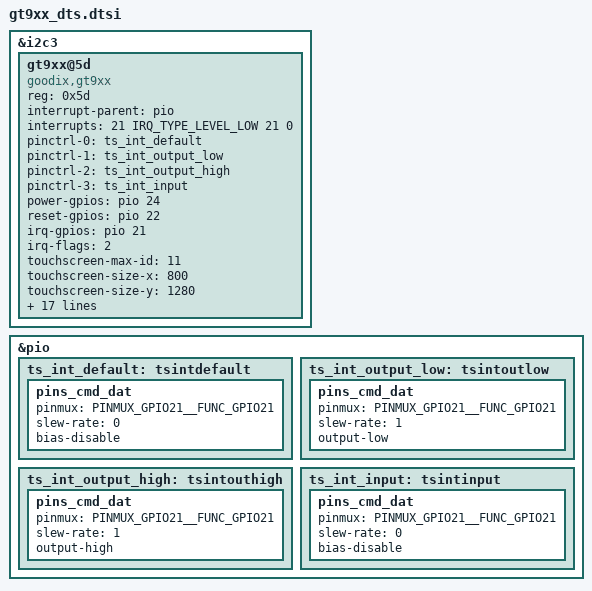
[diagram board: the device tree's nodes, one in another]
// SPDX-License-Identifier: GPL-2.0+
/*
 * Copyright (c) 2019 MediaTek Inc.
 */
&i2c3 {
	gt9xx@5d {
		compatible = "goodix,gt9xx";
		reg = <0x5d>; 
		status = "okay";
		interrupt-parent = <&pio>;
		interrupts = <21 IRQ_TYPE_LEVEL_LOW 21 0>;
		pinctrl-names = "default", "int-output-low","int-output-high", "int-input";
		pinctrl-0 = <&ts_int_default>;
		pinctrl-1 = <&ts_int_output_low>;
		pinctrl-2 = <&ts_int_output_high>;
		pinctrl-3 = <&ts_int_input>;
	
		power-gpios = <&pio 24 0>;
		reset-gpios = <&pio 22 0>;
		irq-gpios = <&pio 21 0>;
		irq-flags = <2>;
	
		touchscreen-max-id = <11>;
		touchscreen-size-x = <800>;
		touchscreen-size-y = <1280>;
		touchscreen-max-w = <512>;
		touchscreen-max-p = <512>;
		touchscreen-key-map = <172>, <158>; /*KEY_HOMEPAGE=172, KEY_BACK=158，KEY_MENU=139*/
		
		goodix,slide-wakeup = <0>;
		goodix,type-a-report = <0>;
		goodix,driver-send-cfg = <0>;
		goodix,resume-in-workqueue = <0>;
		goodix,int-sync = <0>;
		goodix,swap-x2y = <0>;
		goodix,reverse-x = <0>;
		goodix,reverse-y = <0>;
		goodix,esd-protect = <1>;
		goodix,auto-update-cfg = <0>;
		goodix,power-off-sleep = <0>;
		goodix,pen-suppress-finger = <0>;
		goodix,cfg-group0 = [
			63 20 03 00 05 0A 3D 00 01 08 1E 08 5A 3C 03 05 00 00 00 00 00 00 04 18 1A 1E 14 90 30 AA 2E 30 12 0C 00 00 00 DA 03 11 00 00 00 00 00 00 00 00 00 00 00 1E 46 94 D5 13 0C 87 00 04 A5 20 00 91 26 00 81 2D 00 73 36 00 69 40 00 69 00 00 00 00 00 00 00 00 00 00 00 00 00 00 00 00 00 00 00 00 00 00 00 00 00 00 00 00 10 00 00 00 00 00 00 00 00 01 04 05 06 07 08 09 0C 0D 0E 0F 10 11 14 15 16 17 18 19 00 00 00 00 00 00 00 00 00 00 00 02 04 06 07 08 0A 0C 0D 0E 0F 10 11 12 13 14 19 1B 1C 1E 1F 20 21 22 23 24 25 26 27 28 29 2A 00 00 00 00 00 00 00 00 00 00 DA 01
		];
	};
};

&pio {
	ts_int_default: tsintdefault {
		pins_cmd_dat {
			pinmux = <PINMUX_GPIO21__FUNC_GPIO21>;
			slew-rate = <0>;
			bias-disable;
		};
	};
	ts_int_output_low: tsintoutlow {
		pins_cmd_dat {
			pinmux = <PINMUX_GPIO21__FUNC_GPIO21>;
			slew-rate = <1>;
			output-low;
		};
	};
	ts_int_output_high: tsintouthigh {
		pins_cmd_dat {
			pinmux = <PINMUX_GPIO21__FUNC_GPIO21>;
			slew-rate = <1>;
			output-high;
		};
	};
	ts_int_input: tsintinput {
		pins_cmd_dat {
			pinmux = <PINMUX_GPIO21__FUNC_GPIO21>;
			slew-rate = <0>;
			bias-disable;
		};
	};
};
